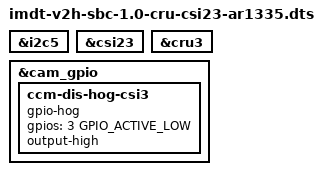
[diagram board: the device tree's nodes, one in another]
// SPDX-License-Identifier: GPL-2.0+
/*
 * Device Tree Overlay for CSI2-3 AR1335 on IMDT-V2H-SBC
 * Copyright (C) 2026 Renesas Electronics Corporation
 */
/dts-v1/;
/plugin/;

#include <dt-bindings/gpio/gpio.h>

&i2c5 {
	status = "okay";
};

&csi23 {
	status = "okay";
};

&cru3 {
	status = "okay";
};

&cam_gpio {
	ccm-dis-hog-csi3 {
		gpio-hog;
		gpios = <3 GPIO_ACTIVE_LOW>;
		output-high;
	};
};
